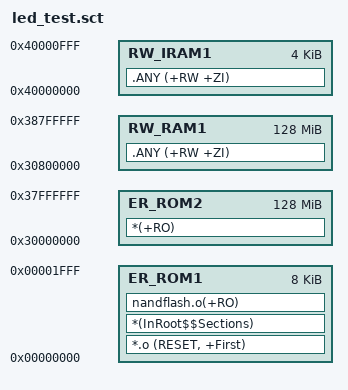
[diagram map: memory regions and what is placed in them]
; *************************************************************
; *** Scatter-Loading Description File generated by uVision ***
; *************************************************************

LR_ROM1 0x00000000 0x00200000  {    ; load region size_region
  ER_ROM1 0x00000000 0x00002000  {  ; load address = execution address	 启动代码部分
   *.o (RESET, +First)
   *(InRoot$$Sections) ;初始化区，根据sct文件，自动生成完成加载的拷贝代码
   nandflash.o(+RO)
  }
  ER_ROM2 0x30000000 0x08000000 {  ; load address = execution address ，程序执行地址
   *(+RO)
  }
   RW_RAM1 0x30800000 0x08000000  {  ; RW data
   .ANY (+RW +ZI)
  }
  RW_IRAM1 0x40000000 0x00001000  {  ; RW data
   .ANY (+RW +ZI)
  }
}

